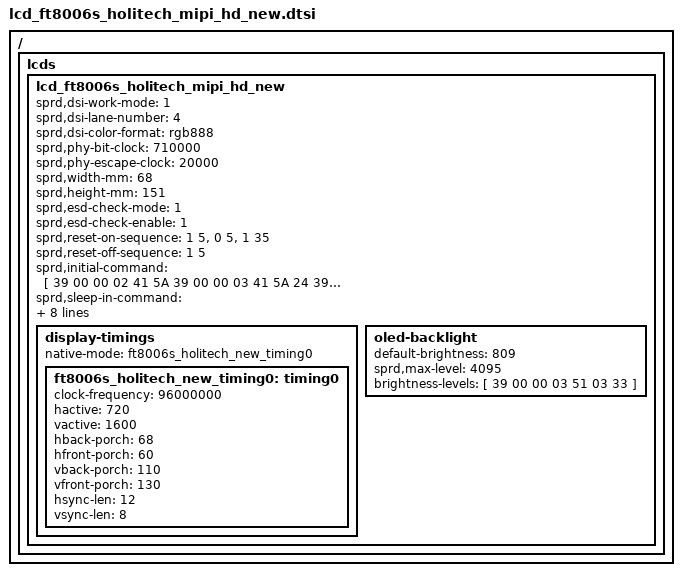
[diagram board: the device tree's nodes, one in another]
/ {
	fragment {
		target-path = "/";
		__overlay__ {
			lcds {
				lcd_ft8006s_holitech_mipi_hd_new: lcd_ft8006s_holitech_mipi_hd_new {
					sprd,dsi-work-mode = <1>; /* video burst mode*/
					sprd,dsi-lane-number = <4>;
					sprd,dsi-color-format = "rgb888";

					sprd,phy-bit-clock = <710000>;  /* kbps */
					sprd,phy-escape-clock = <20000>;/* kHz */

					sprd,width-mm = <68>;
					sprd,height-mm = <151>;

					sprd,esd-check-mode = <1>;
					sprd,esd-check-enable = <1>;

					sprd,reset-on-sequence = <1 5>, <0 5>, <1 35>;
					sprd,reset-off-sequence = <1 5>;

					sprd,initial-command = [
						39 00 00 02 41 5A
						39 00 00 03 41 5A 24
						39 00 00 02 90 5A
						39 00 00 03 41 5A 08
						39 00 00 04 80 C8 2C 01
						39 00 00 03 41 5A 09
						39 00 00 11 80 5A 51 B5 2A 6C E5 4A 01 40 62 0F 82 20 08 F0 B7
						39 00 00 11 90 00 24 42 0A E3 91 A4 F0 B9 61 69 20 69 81 26 00
						39 00 00 11 A0 51 55 55 00 A0 4D 06 11 0D 60 5A FF FF 03 A5 E6
						39 00 00 11 B0 08 C9 16 64 0B 00 00 11 07 60 00 FF FF 03 FF 34
						39 00 00 09 C0 0C 3F 1F 9F 0F 00 08 00
						39 00 00 03 41 5A 0A
						39 00 00 11 80 FF 83 8D 03 00 0B 14 20 2F 3E 43 75 3F 7F B2 75
						39 00 00 11 90 92 5F 59 47 35 23 14 0B 00 0B 14 20 2F 3E 43 75
						39 00 00 0E A0 3F 7F B2 75 92 5F 59 47 35 23 14 0B 00
						39 00 00 03 41 5A 0B
						39 00 00 11 80 00 00 20 44 08 00 60 47 00 00 10 22 04 00 B0 23
						39 00 00 03 90 15 00
						39 00 00 03 41 5A 0C
						39 00 00 11 80 BA 68 68 01 32 6E 90 0B 00 60 15 00 50 15 56 51
						39 00 00 11 90 15 55 61 15 00 60 15 00 50 15 56 51 15 55 61 95
						39 00 00 11 A0 AB 18 00 05 00 05 00 05 00 49 29 84 52 01 09 00
						39 00 00 03 B0 00 00
						39 00 00 03 41 5A 0D
						39 00 00 08 80 F0 B1 71 EF 4B C0 80
						39 00 00 03 41 5A 0E
						39 00 00 09 80 FF 01 55 55 32 88 88 1C
						39 00 00 03 41 5A 0F
						39 00 00 11 80 D1 07 70 E0 11 A0 63 08 52 51 68 49 03 52 4C 4C
						39 00 00 11 90 68 68 68 4C 4C 7C 14 00 20 06 C2 00 04 06 0C 00
						39 00 00 05 A0 00 92 00 00
						39 00 00 03 41 5A 10
						39 00 00 11 80 00 00 03 E7 1F 17 10 48 80 AA D0 18 30 88 41 8A
						39 00 00 10 90 39 28 A9 C5 9A 7B F0 07 7E E0 07 7E 20 10 00
						39 00 00 03 41 5A 11
						39 00 00 11 80 49 77 03 40 CA F4 FF A3 40 08 C4 06 A1 D8 24 18
						39 00 00 11 90 30 C6 66 C1 80 51 15 CB E5 D2 68 6C 36 1D 04 C8
						39 00 00 11 A0 B0 D9 88 60 B0 81 40 1A 1B 48 63 03 B9 00 1C 80
						39 00 00 11 B0 50 30 00 E0 E1 01 00 28 0E 06 43 55 55 55 55 55
						39 00 00 11 C0 15 11 11 11 11 11 11 11 88 C6 E3 81 00 20 00 21
						39 00 00 11 D0 42 88 20 00 10 00 40 80 24 32 04 41 06 00 00 00
						39 00 00 11 E0 00 00 00 00 00 00 00 00 00 00 92 04 00 85 11 0C
						39 00 00 10 F0 00 00 40 00 00 00 00 5E 4A 01 78 00 08 00 00
						39 00 00 03 41 5A 12
						39 00 00 11 80 00 00 00 00 00 02 03 00 00 00 00 02 03 01 41 37
						39 00 00 11 90 F1 E7 00 00 00 00 00 00 00 00 00 00 00 2D 23 05
						39 00 00 08 A0 FB 08 2D 23 05 FB 0C
						39 00 00 03 41 5A 13
						39 00 00 11 80 FD 0F 00 0C 00 00 00 00 01 08 01 1C 44 0C CE E7
						39 00 00 0F 90 62 0E 24 98 AC 21 01 00 D0 93 24 49 06 20
						39 00 00 03 41 5A 14
						39 00 00 11 80 01 02 41 36 E9 EF F7 FB FD 7E 00 00 00 90 C5 89
						39 00 00 11 90 27 3D 20 46 3C E9 01 F1 E1 49 0F 88 0D 4F 7A 00
						39 00 00 11 A0 00 00 00 00 00 00 00 00 00 00 00 00 00 00 00 00
						39 00 00 11 B0 00 00 00 00 00 00 00 00 00 1C B2 21 2B 00 40 A1
						39 00 00 11 C0 50 78 07 5A F2 90 51 1C 6F 40 4B 1E 32 8A E3 05
						39 00 00 11 D0 68 C9 43 46 71 BC 02 2D 79 C8 28 8E 77 A1 25 0F
						39 00 00 11 E0 19 C5 F1 26 B4 E4 21 A3 38 DE 83 96 3C 64 14 C7
						39 00 00 11 F0 5B D0 92 87 8C E2 18 01 BF 5F 08 00 00 00 00 00
						39 00 00 03 41 5A 15
						39 00 00 11 80 00 00 00 00 00 00 00 00 00 00 00 00 12 D8 E0 F7
						39 00 00 11 90 F3 00 20 CB 85 AA D5 06 91 91 77 A1 6A B5 41 64
						39 00 00 11 A0 64 00 00 00 00 00 00 00 00 00 00 00 00 00 00 90
						39 00 00 11 B0 75 A1 6A B5 00 00 00 40 12 00 00 00 80 D6 0C 4D
						39 00 00 11 C0 C9 22 41 C1 50 9C B6 6D DB B6 6D DB B6 6D C9 D0
						39 00 00 11 D0 A4 20 13 64 10 02 68 DB B6 6D DB B6 6D DB D6 0C
						39 00 00 11 E0 4D 88 22 41 80 40 98 B6 6D DB B6 6D DB B6 6D C9
						39 00 00 11 F0 D0 B4 24 13 74 14 43 68 DB B6 6D DB B6 6D 5B C0
						39 00 00 03 41 5A 16
						39 00 00 11 80 C3 43 41 01 00 00 00 00 00 00 00 00 00 00 00 00
						39 00 00 07 90 00 00 00 00 F0 20
						39 00 00 03 41 5A 18
						39 00 00 11 80 EF BD F7 DE 7B EF BD 07 08 08 0A 0C 0C 0C 0C 0C
						39 00 00 11 90 0C 0C 0C 5C 09 A8 AA AA AA AA AA AA AA AA AA 5A
						39 00 00 11 A0 59 59 59 59 59 59 59 59 59 59 59 09 04 FF 00 80
						39 00 00 10 B0 80 00 04 20 00 01 08 40 00 02 10 80 00 04 00
						39 00 00 03 41 5A 19
						39 00 00 11 80 C0 AF A3 9B 92 8D 8A 86 84 83 82 81 00 50 F6 CF
						39 00 00 11 90 FC 2F F3 EF CF BF 0F FF AF B5 71 0E 6C 4A 69 08
						39 00 00 05 A0 00 00 04 00
						39 00 00 03 41 5A 1A
						39 00 00 11 80 00 04 08 0C 00 10 14 18 1C 00 20 28 30 38 00 40
						39 00 00 11 90 48 50 58 00 60 68 70 78 00 80 88 90 98 00 A0 A8
						39 00 00 11 A0 B0 B8 00 C0 C8 D0 D8 00 E0 E8 F0 F8 00 FC FE FF
						39 00 00 11 B0 00 00 04 08 0C 00 10 14 18 1C 00 20 28 30 38 00
						39 00 00 11 C0 40 48 50 58 00 60 68 70 78 00 80 88 90 98 00 A0
						39 00 00 11 D0 A8 B0 B8 00 C0 C8 D0 D8 00 E0 E8 F0 F8 00 FC FE
						39 00 00 11 E0 FF 00 00 04 08 0C 00 10 14 18 1C 00 20 28 30 38
						39 00 00 11 F0 00 40 48 50 58 00 60 68 70 78 00 80 88 90 98 00
						39 00 00 03 41 5A 1B
						39 00 00 11 80 A0 A8 B0 B8 00 C0 C8 D0 D8 00 E0 E8 F0 F8 00 FC
						39 00 00 05 90 FE FF 00 00
						39 00 00 03 41 5A 20
						39 00 00 08 80 74 00 00 00 00 00 00
						39 00 00 03 41 5A 22
						39 00 00 0E 80 2D D3 00 15 50 55 55 55 01 00 50 9F 00
						39 00 00 03 41 5A 23
						39 00 00 11 80 01 05 00 05 00 00 00 00 00 00 00 00 00 00 00 00
						39 00 00 0D 90 FF 0F 00 00 00 03 00 00 00 FF 07 35
						39 00 00 03 41 5A 24
						39 00 00 11 80 00 03 00 FF FF 20 00 00 00 00 00 00 00 00 20 EB
						39 00 00 11 90 5A 5A 5A 55 00 00 00 00 00 00 00 00 00 00 00 00
						39 00 00 02 42 24
						39 00 00 02 90 00
						39 00 00 03 41 5A 2F
						39 00 00 02 19 00
						39 00 00 02 4C 03
						39 00 00 03 51 00 00
						39 00 00 02 53 24
						39 78 00 01 11
						39 00 00 02 35 00
						39 00 00 02 55 00
						39 0a 00 01 29
					];

					sprd,sleep-in-command = [
						13 0A 00 01 28
						13 82 00 01 10
						39 00 00 02 17 5A
						39 14 00 02 18 5A
					];
					sprd,sleep-out-command = [
						13 78 00 01 11
						13 14 00 01 29
					];
					sprd,cabc-off-command = [
						39 00 00 02 55 00
						];
					sprd,cabc-ui-command = [
						39 00 00 02 55 03
						];
					sprd,cabc-still-command = [
						39 00 00 02 55 03
						];
					sprd,cabc-moving-command = [
						39 00 00 02 55 03
						];
					display-timings {
						native-mode = <&ft8006s_holitech_new_timing0>;
						ft8006s_holitech_new_timing0: timing0 {
							clock-frequency = <96000000>;
							hactive = <720>;
							vactive = <1600>;
							hback-porch = <68>;
							hfront-porch = <60>;
							vback-porch = <110>;
							vfront-porch = <130>;
							hsync-len = <12>;
							vsync-len = <8>;
						};
					};

					oled-backlight {
						default-brightness = <809>;
						sprd,max-level = <4095>;
						brightness-levels = [
							39 00 00 03 51 03 33 
						];
					};
				};
			};
		};
	};
};
